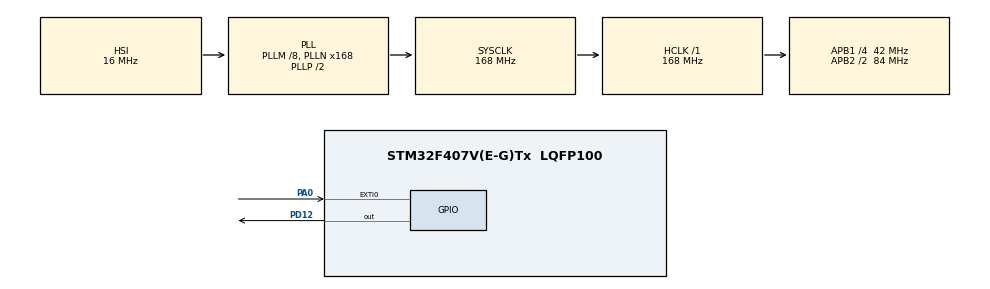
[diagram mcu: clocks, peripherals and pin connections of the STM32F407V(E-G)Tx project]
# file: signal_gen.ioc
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Mcu.Family=STM32F4
Mcu.Name=STM32F407V(E-G)Tx
Mcu.Package=LQFP100
NVIC.EXTI0_IRQn=true\:0\:0\:false\:false\:true\:true\:true\:true
NVIC.PriorityGroup=NVIC_PRIORITYGROUP_4
NVIC.TIM4_IRQn=true\:0\:0\:false\:false\:true\:true\:true\:true
PA0-WKUP.Signal=GPXTI0
PD12.Signal=GPIO_Output
ProjectManager.HeapSize=0x200
ProjectManager.StackSize=0x400
ProjectManager.TargetToolchain=STM32CubeIDE
RCC.48MHZClocksFreq_Value=84000000
RCC.AHBFreq_Value=168000000
RCC.APB1CLKDivider=RCC_HCLK_DIV4
RCC.APB1Freq_Value=42000000
RCC.APB1TimFreq_Value=84000000
RCC.APB2CLKDivider=RCC_HCLK_DIV2
RCC.APB2Freq_Value=84000000
RCC.APB2TimFreq_Value=168000000
RCC.CortexFreq_Value=168000000
RCC.HCLKFreq_Value=168000000
RCC.HSE_VALUE=25000000
RCC.HSI_VALUE=16000000
RCC.LSE_VALUE=32768
RCC.PLLM=8
RCC.PLLN=168
RCC.SYSCLKFreq_VALUE=168000000
RCC.SYSCLKSource=RCC_SYSCLKSOURCE_PLLCLK
RCC.VCOOutputFreq_Value=336000000
TIM4.AutoReloadPreload=TIM_AUTORELOAD_PRELOAD_DISABLE
TIM4.CounterMode=TIM_COUNTERMODE_UP
TIM4.Period=1
TIM4.Prescaler=4205
VP_TIM4_VS_ClockSourceINT.Mode=Internal
board=custom

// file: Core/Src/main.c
/* USER CODE BEGIN Header */
/**
  ******************************************************************************
  * @file           : main.c
  * @brief          : Main program body
  ******************************************************************************
  * @attention
  *
  * Copyright (c) 2024 STMicroelectronics.
  * All rights reserved.
  *
  * This software is licensed under terms that can be found in the LICENSE file
  * in the root directory of this software component.
  * If no LICENSE file comes with this software, it is provided AS-IS.
  *
  ******************************************************************************
  */
/* USER CODE END Header */
#include "main.h"

TIM_HandleTypeDef htim4;

/* USER CODE BEGIN PV */
//uint8_t pattern[] = {0, 1,1,1, 0,0,0,0,0,0,0, 1, 0,0,0,0,0,0, 1, 0,0,0,0,0, 1, 0, 1,1, 0,0, 1,1, 0, 1, 0,0,0,0, 1,1,1, 0,1};
uint8_t pattern[] = {0,0,0,0,0,0,0,1,0,0,0,1,0,0,0,0,0,1,0,1,1,0,0,1,0,1,0,1,1,1,1,1,0,1,1,0,1,0,0,1,1,0,1,1,0,1,1,1,1,0,1};

uint8_t idx = 0;
uint8_t stuffedPattern[128];
uint8_t slength = 0;
uint8_t buf[100];
/* USER CODE END PV */

void SystemClock_Config(void);
static void MX_GPIO_Init(void);
static void MX_TIM4_Init(void);
/* USER CODE BEGIN PFP */
void addBitStuffing(uint8_t input[], uint8_t output[], uint8_t length, uint8_t *output_length) {
    uint8_t consecutive_count0 = 1;
    uint8_t consecutive_count1 = 1;
    *output_length = 0;

    output[(*output_length)++] = input[0];

    for (uint8_t i = 1; i < length; i++) {
        output[(*output_length)++] = input[i];

        if (input[i] == input[i - 1] && input[i] == 0) {
            consecutive_count0++;
        } else {
        	if(input[i] == input[i-1] && input[1] == 1)
            consecutive_count1++;
        	else {
        		consecutive_count0 = 1;
        		consecutive_count1 = 1;
        	}
        }

        if (consecutive_count0 == 5) {
            output[(*output_length)++] = 1;
            consecutive_count0 = 1;
        }
        if(consecutive_count1 == 5) {
        	output[(*output_length)++] = 0;
        	consecutive_count1 = 1;
        }
    }
}
/* USER CODE END PFP */

int main(void)
{

  /* MCU Configuration--------------------------------------------------------*/

  /* Reset of all peripherals, Initializes the Flash interface and the Systick. */
  HAL_Init();

  /* Configure the system clock */
  SystemClock_Config();

  /* Initialize all configured peripherals */
  MX_GPIO_Init();
  MX_TIM4_Init();
  /* USER CODE BEGIN 2 */

  addBitStuffing(pattern, stuffedPattern, sizeof(pattern) / sizeof(pattern[0]), &slength);
  /* USER CODE END 2 */

  /* Infinite loop */
  /* USER CODE BEGIN WHILE */
  while (1)
  {
		if(idx == slength)
		{
			HAL_TIM_Base_Stop_IT(&htim4);
			idx = 0;
			HAL_GPIO_WritePin(GPIOD, GPIO_PIN_12, GPIO_PIN_SET);
		}
    /* USER CODE END WHILE */

  }
}

void SystemClock_Config(void)
{
  RCC_OscInitTypeDef RCC_OscInitStruct = {0};
  RCC_ClkInitTypeDef RCC_ClkInitStruct = {0};

  /** Configure the main internal regulator output voltage
  */
  __HAL_RCC_PWR_CLK_ENABLE();
  __HAL_PWR_VOLTAGESCALING_CONFIG(PWR_REGULATOR_VOLTAGE_SCALE1);

  /** Initializes the RCC Oscillators according to the specified parameters
  * in the RCC_OscInitTypeDef structure.
  */
  RCC_OscInitStruct.OscillatorType = RCC_OSCILLATORTYPE_HSI;
  RCC_OscInitStruct.HSIState = RCC_HSI_ON;
  RCC_OscInitStruct.HSICalibrationValue = RCC_HSICALIBRATION_DEFAULT;
  RCC_OscInitStruct.PLL.PLLState = RCC_PLL_ON;
  RCC_OscInitStruct.PLL.PLLSource = RCC_PLLSOURCE_HSI;
  RCC_OscInitStruct.PLL.PLLM = 8;
  RCC_OscInitStruct.PLL.PLLN = 168;
  RCC_OscInitStruct.PLL.PLLP = RCC_PLLP_DIV2;
  RCC_OscInitStruct.PLL.PLLQ = 4;
  if (HAL_RCC_OscConfig(&RCC_OscInitStruct) != HAL_OK)
  {
    Error_Handler();
  }

  /** Initializes the CPU, AHB and APB buses clocks
  */
  RCC_ClkInitStruct.ClockType = RCC_CLOCKTYPE_HCLK|RCC_CLOCKTYPE_SYSCLK
                              |RCC_CLOCKTYPE_PCLK1|RCC_CLOCKTYPE_PCLK2;
  RCC_ClkInitStruct.SYSCLKSource = RCC_SYSCLKSOURCE_PLLCLK;
  RCC_ClkInitStruct.AHBCLKDivider = RCC_SYSCLK_DIV1;
  RCC_ClkInitStruct.APB1CLKDivider = RCC_HCLK_DIV4;
  RCC_ClkInitStruct.APB2CLKDivider = RCC_HCLK_DIV2;

  if (HAL_RCC_ClockConfig(&RCC_ClkInitStruct, FLASH_LATENCY_5) != HAL_OK)
  {
    Error_Handler();
  }
}

static void MX_TIM4_Init(void)
{

  TIM_ClockConfigTypeDef sClockSourceConfig = {0};
  TIM_MasterConfigTypeDef sMasterConfig = {0};

  htim4.Instance = TIM4;
  htim4.Init.Prescaler = 4205;
  htim4.Init.CounterMode = TIM_COUNTERMODE_UP;
  htim4.Init.Period = 1;
  htim4.Init.ClockDivision = TIM_CLOCKDIVISION_DIV1;
  htim4.Init.AutoReloadPreload = TIM_AUTORELOAD_PRELOAD_DISABLE;
  if (HAL_TIM_Base_Init(&htim4) != HAL_OK)
  {
    Error_Handler();
  }
  sClockSourceConfig.ClockSource = TIM_CLOCKSOURCE_INTERNAL;
  if (HAL_TIM_ConfigClockSource(&htim4, &sClockSourceConfig) != HAL_OK)
  {
    Error_Handler();
  }
  sMasterConfig.MasterOutputTrigger = TIM_TRGO_RESET;
  sMasterConfig.MasterSlaveMode = TIM_MASTERSLAVEMODE_DISABLE;
  if (HAL_TIMEx_MasterConfigSynchronization(&htim4, &sMasterConfig) != HAL_OK)
  {
    Error_Handler();
  }

}

static void MX_GPIO_Init(void)
{
  GPIO_InitTypeDef GPIO_InitStruct = {0};

  /* GPIO Ports Clock Enable */
  __HAL_RCC_GPIOA_CLK_ENABLE();
  __HAL_RCC_GPIOD_CLK_ENABLE();

  /*Configure GPIO pin Output Level */
  HAL_GPIO_WritePin(GPIOD, GPIO_PIN_12, GPIO_PIN_RESET);

  /*Configure GPIO pin : PA0 */
  GPIO_InitStruct.Pin = GPIO_PIN_0;
  GPIO_InitStruct.Mode = GPIO_MODE_IT_RISING;
  GPIO_InitStruct.Pull = GPIO_NOPULL;
  HAL_GPIO_Init(GPIOA, &GPIO_InitStruct);

  /*Configure GPIO pin : PD12 */
  GPIO_InitStruct.Pin = GPIO_PIN_12;
  GPIO_InitStruct.Mode = GPIO_MODE_OUTPUT_PP;
  GPIO_InitStruct.Pull = GPIO_NOPULL;
  GPIO_InitStruct.Speed = GPIO_SPEED_FREQ_LOW;
  HAL_GPIO_Init(GPIOD, &GPIO_InitStruct);

  /* EXTI interrupt init*/
  HAL_NVIC_SetPriority(EXTI0_IRQn, 0, 0);
  HAL_NVIC_EnableIRQ(EXTI0_IRQn);

/* USER CODE BEGIN MX_GPIO_Init_2 */
  HAL_GPIO_WritePin(GPIOD, GPIO_PIN_12, GPIO_PIN_SET);
/* USER CODE END MX_GPIO_Init_2 */
}

void Error_Handler(void)
{
  __disable_irq();
  while (1)
  {
  }
}
